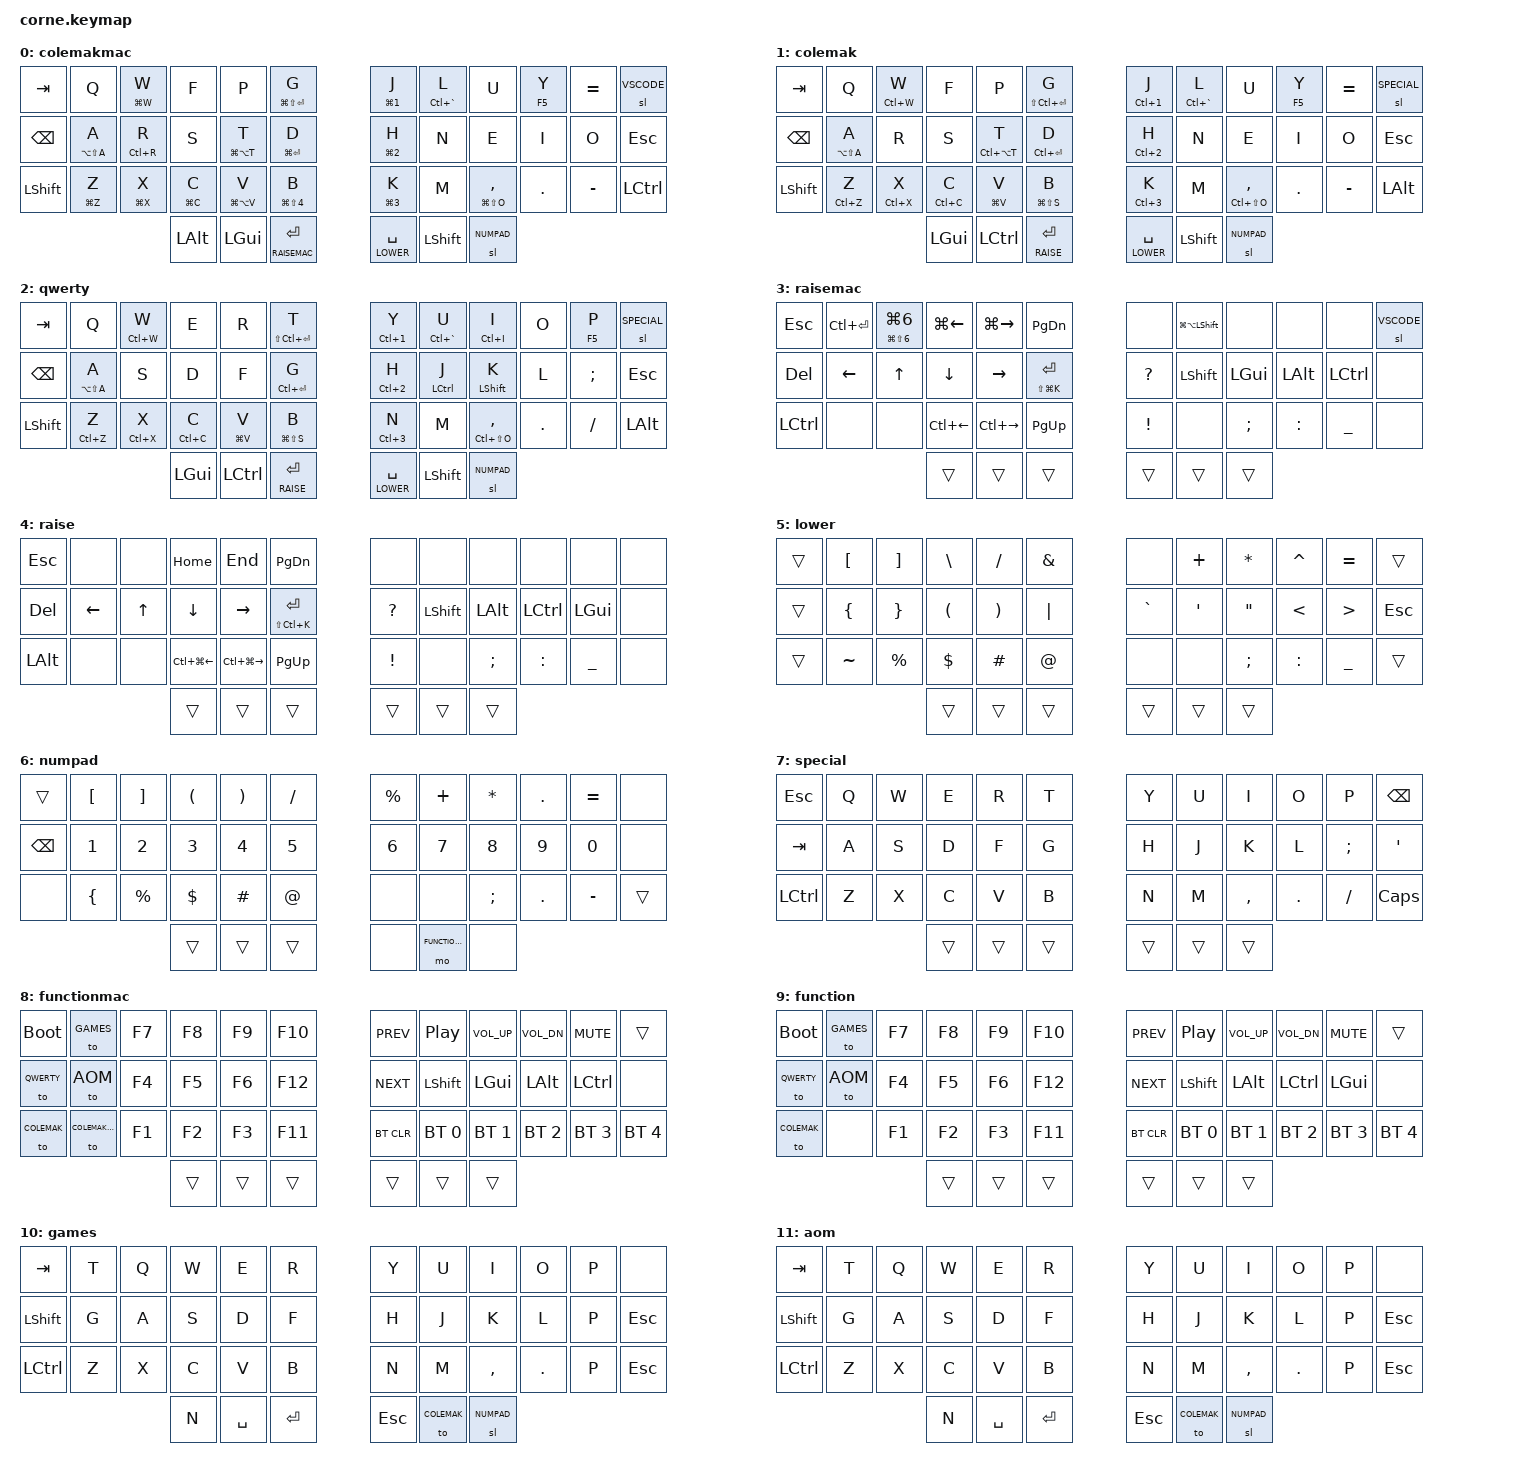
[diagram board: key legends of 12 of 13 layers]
/*
 * Copyright (c) 2020 The ZMK Contributors
 *
 * SPDX-License-Identifier: MIT
 */

#include <behaviors.dtsi>
#include <dt-bindings/zmk/outputs.h>
#include <dt-bindings/zmk/rgb.h>
#include <dt-bindings/zmk/keys.h>
#include <dt-bindings/zmk/bt.h>

//Layer definitions
#define COLEMAKMAC 0
#define COLEMAK 1
#define QWERTY 2
#define RAISEMAC 3
#define RAISE 4
#define LOWER 5
#define NUMPAD 6
#define SPECIAL 7
#define FUNCTIONMAC 8
#define FUNCTION 9
#define GAMES 10
#define AOM 11
#define VSCODE 12
#define MOOM 13
/*#define MINERAISE 8
#define ADJUST 9
*/

&caps_word {
    continue-list = <UNDERSCORE MINUS>;
};

/ {

    combos {
        compatible = "zmk,combos";
        combo_F12 {
            timeout-ms = <50>;
            key-positions = <17 16>;
            bindings = <&kp F12>;
            layers = <QWERTY COLEMAK COLEMAKMAC>;
        };
        combo_F2 {
            timeout-ms = <50>;
            key-positions = <26 27>;
            bindings = <&kp F2>;
            layers = <QWERTY COLEMAK COLEMAKMAC>;
        };
        combo_F3 {
            timeout-ms = <50>;
            key-positions = <3 4>;
            bindings = <&kp F3>;
            layers = <QWERTY COLEMAK COLEMAKMAC>;
        };
        combo_SQT {
            timeout-ms = <50>;
            key-positions = <8 9>;
            bindings = <&kp SQT>;
            layers = <QWERTY COLEMAK COLEMAKMAC>;
        };
        combo_Format {
            timeout-ms = <50>;
            key-positions = <5 4>;
            bindings = <&kp LA(LS(F))>;
            layers = <QWERTY COLEMAK COLEMAKMAC>;
        };
        combo_AltTab {
            timeout-ms = <50>;
            key-positions = <2 3>;
            bindings = <&kp LA(TAB)>;
            layers = <QWERTY COLEMAK>;
        };
        combo_AltRigth {
            timeout-ms = <50>;
            key-positions = <15 16>;
            bindings = <&kp LA(RIGHT)>;
            layers = <QWERTY COLEMAK>;
        };
        combo_AltLeft {
            timeout-ms = <50>;
            key-positions = <14 15>;
            bindings = <&kp LA(LEFT)>;
            layers = <QWERTY COLEMAK>;
        };
        combo_AltTab_MAC {
            timeout-ms = <50>;
            key-positions = <2 3>;
            bindings = <&kp LG(TAB)>;
            layers = <COLEMAKMAC>;
        };
        combo_AltRigth_MAC {
            timeout-ms = <50>;
            key-positions = <15 16>;
            bindings = <&kp LC(MINUS)>;
            layers = <COLEMAKMAC>;
        };
        combo_AltLeft_MAC {
            timeout-ms = <50>;
            key-positions = <14 15>;
            bindings = <&kp LC(LS(MINUS))>;
            layers = <COLEMAKMAC>;
        };
        combo_MissionControl {
            timeout-ms = <50>;
            key-positions = <14 15>;
            bindings = <&kp LC(UP)>;
            layers = <RAISEMAC>;
        };
        combo_Caps {
            timeout-ms = <50>;
            key-positions = <1 2>;
            bindings = <&caps_word>;
            layers = <QWERTY COLEMAK COLEMAKMAC>;
        };
    };
    behaviors {
        mt_s: ctrl_shift {
            compatible = "zmk,behavior-hold-tap";
            label = "HOMEROW_MODS_CTRL_SHIFT";
            #binding-cells = <2>;
            tapping-term-ms = <180>;
            quick_tap_ms = <0>;
            flavor = "balanced";
            bindings = <&kp>, <&kp>;
        };
        mt_m: medium {
            compatible = "zmk,behavior-hold-tap";
            label = "Fast hold";
            #binding-cells = <2>;
            tapping-term-ms = <240>;
            quick_tap_ms = <0>;
            flavor = "tap-preferred";
            bindings = <&kp>, <&kp>;
        };
        mt_l: alt_gui {
            compatible = "zmk,behavior-hold-tap";
            label = "HOMEROW_MODS_ALT_GUI";
            #binding-cells = <2>;
            tapping-term-ms = <300>;
            quick_tap_ms = <0>;
            flavor = "tap-preferred";
            bindings = <&kp>, <&kp>;
        };

    };

    keymap {
            compatible = "zmk,keymap";

            colemakmac {
// GASC home row mods. Layer key mods. Mod tap for zxcv. Mod tap for backspace/shift
// -----------------------------------------------------------------------------------------
// | 0   |  Q  |  W  |  F  |  P  |  G  |    6 |  J  |  L  |  U  |  Y  |  ;  |      |
// | 12   |  A  |  R  |  S  |  T  |  D  |  18 |  H  |  N  |  E  |  I  |  O  |  '   |
// | 24   |  Z  |  X  |  C  |  V  |  B  |  30 |  K  |  M  |  ,  |  .  |  /  | CAPS |
//                       | TAB | LWR | SPC |   | ENT | RSE | BSPC|
//                             | ESC |               | DEL |
//vscode LG(LS(0)) Go to Symbol
// mac LG(LS(N4)) screenshot (add ctrl to copy only)
        bindings = <
    &kp TAB     &kp Q              &mt_l LG(W) W    &kp F           &kp P              &mt_m LG(LS(ENTER))  G  /**/    &mt_m LG(N1) J     &mt_m LC(GRAVE) L   &kp U                     &mt_m F5 Y     &kp EQUAL        &sl VSCODE
    &kp BSPC    &mt_l LA(LS(A)) A  &mt_l LC(R) R    &kp S           &mt_l LG(LA(T)) T  &mt_m LG(ENTER)      D  /**/    &mt_m LG(N2) H     &kp N               &kp E                     &kp I          &kp O            &kp ESC
    &kp LSHFT   &mt_l LG(Z) Z      &mt_l LG(X) X    &mt_l LG(C) C   &mt_m LG(LA(V)) V  &mt_m LG(LS(N4))     B  /**/    &mt_m LG(N3) K     &kp M               &mt_m LG(LS(O)) COMMA      &kp DOT        &kp MINUS       &kp LCTRL
                                                &kp  LALT  &kp LGUI   &lt RAISEMAC ENTER                       /**/    &lt LOWER SPACE   &kp LSHFT   &sl NUMPAD
                        >;
            };      

            colemak {
// GASC home row mods. Layer key mods. Mod tap for zxcv. Mod tap for backspace/shift
// -----------------------------------------------------------------------------------------
// | 0   |  Q  |  W  |  F  |  P  |  G  |    6 |  J  |  L  |  U  |  Y  |  ;  |      |
// | 12   |  A  |  R  |  S  |  T  |  D  |  18 |  H  |  N  |  E  |  I  |  O  |  '   |
// | 24   |  Z  |  X  |  C  |  V  |  B  |  30 |  K  |  M  |  ,  |  .  |  /  | CAPS |
//                       | TAB | LWR | SPC |   | ENT | RSE | BSPC|
//                             | ESC |               | DEL |

        bindings = <
    &kp TAB     &kp Q              &mt_l LC(W) W    &kp F           &kp P              &mt_m LS(LC(ENTER))  G  /**/    &mt_m LC(N1) J     &mt_m LC(GRAVE) L   &kp U                     &mt_m F5 Y     &kp EQUAL        &sl SPECIAL
    &kp BSPC    &mt_l LA(LS(A)) A  &kp R            &kp S           &mt_l LC(LA(T)) T  &mt_m LC(ENTER)      D  /**/    &mt_m LC(N2) H     &kp N               &kp E                     &kp I          &kp O            &kp ESC
    &kp LSHFT   &mt_l LC(Z) Z      &mt_l LC(X) X    &mt_l LC(C) C   &mt_m LG(V) V      &mt_m LG(LS(S))      B  /**/    &mt_m LC(N3) K     &kp M               &mt_m LC(LS(O)) COMMA      &kp DOT        &kp MINUS       &kp LALT
                                                &kp LGUI   &kp LCTRL   &lt RAISE ENTER                         /**/    &lt LOWER SPACE   &kp LSHFT   &sl NUMPAD
                        >;
            };


            qwerty {
// GASC home row mods. Layer key mods. Mod tap for zxcv. Mod tap for backspace/shift
// -----------------------------------------------------------------------------------------
// |    |  Q  |  W  |  E  |  R  |  T  |   |  Y  |  U  |  I  |  O  |  P  |      |
// |    |  A  |  S  |  D  |  F  |  G  |   |  H  |  J  |  K  |  L  |  ;  |  '   |
// |    |  Z  |  X  |  C  |  V  |  B  |   |  N  |  M  |  ,  |  .  |  /  | CAPS |
//                       | TAB | LWR | SPC |   | ENT | RSE | BSPC|
//                             | ESC |               | DEL |
        bindings = <
    &kp TAB     &kp Q               &mt_l LC(W) W   &kp E           &kp R           &mt_m LS(LC(ENTER)) T   /**/    &mt_m LC(N1) Y   &mt_m LC(GRAVE) U  &mt_l LC(I) I           &kp O        &mt_m F5 P     &sl SPECIAL
    &kp BSPC    &mt_l LA(LS(A)) A   &kp  S          &kp D           &kp F           &mt_m LC(ENTER)     G   /**/    &mt_m LC(N2) H   &mt_s LCTRL J      &mt_s LSHFT K           &kp L        &kp SEMI       &kp ESC
    &kp LSHFT   &mt_l LC(Z) Z       &mt_l LC(X) X   &mt_l LC(C) C   &mt_l LG(V) V   &mt_m LG(LS(S))     B   /**/    &mt_m LC(N3) N   &kp M              &mt_m LC(LS(O)) COMMA   &kp DOT      &kp FSLH       &kp LALT
                                            &kp LGUI   &kp LCTRL   &lt RAISE ENTER                          /**/    &lt LOWER SPACE   &kp LSHFT   &sl NUMPAD
                        >;
            };

            raisemac {
// -----------------------------------------------------------------------------------------
// |      |  1  |  2  |  3  |  4  |  5  |   |  6  |  7  |  8  |  9  |  0  |  DEL |
// |      | HME | PGU | PGD | END | XXX |   | XXX | LFT | DWN |  UP | RGT |      |
// |      | F1  | F2  | F3  | F4  | F5  |   | F6  | F7  | F8  | F9  | F10 | CAPS |
//                    |     |     |     |   |     |     |     |
//vscode: LG (6) open explorer view (double tap: open file) (hold return to active editor)
        bindings = <
    &kp ESC  &kp LC(ENTER)  &mt_m LG(LS(N6)) LG(N6)   &kp LG(LEFT)   &kp LG(RIGHT)      &kp PG_DN             /**/   &none       &kp LG(LA(LSHFT))      &none      &none        &none       &sl VSCODE
    &kp DEL   &kp LEFT      &kp UP                     &kp DOWN       &kp  RIGHT         &mt_m LS(LG(K)) ENTER /**/   &kp QMARK   &kp LSHFT             &kp LGUI   &kp LALT     &kp LCTRL   &none
    &kp LCTRL  &none        &none                    &kp LC(LEFT)   &kp LC(RIGHT)      &kp PG_UP             /**/   &kp EXCL    &none                  &kp SEMI   &kp COLON    &kp UNDER   &none
                                   &trans       &trans                &trans                /**/   &trans      &trans         &trans
                        >;
            };

            raise {
// -----------------------------------------------------------------------------------------
// |      |  1  |  2  |  3  |  4  |  5  |   |  6  |  7  |  8  |  9  |  0  |  DEL |
// |      | HME | PGU | PGD | END | XXX |   | XXX | LFT | DWN |  UP | RGT |      |
// |      | F1  | F2  | F3  | F4  | F5  |   | F6  | F7  | F8  | F9  | F10 | CAPS |
//                    |     |     |     |   |     |     |     |
        bindings = <
    &kp ESC  &none      &none      &kp HOME     &kp END               &kp PG_DN             /**/   &none       &none          &none      &none        &none       &none
    &kp DEL   &kp LEFT  &kp UP   &kp DOWN       &kp  RIGHT            &mt_m LS(LC(K)) ENTER /**/    &kp QMARK   &kp LSHFT      &kp LALT   &kp LCTRL    &kp LGUI    &none
    &kp LALT  &none     &none      &kp LC(LG(LEFT)) &kp LC(LG(RIGHT)) &kp PG_UP             /**/   &kp EXCL    &none          &kp SEMI   &kp COLON    &kp UNDER   &none
                                   &trans       &trans                &trans                /**/    &trans      &trans         &trans
                        >;
            };


            lower {
// -----------------------------------------------------------------------------------------
// |      |  !  |  @  |  #  |  $  |  %  |   |  ^  |  &  |  *  |  {  |  }  | DEL  |
// |      |  -  |  _  |  =  |  +  |  `  |   |  ~  |  (  |  )  |  [  |  ]  |      |
// |      | Und | Cut | Cpy | Pst |     |   | PLY |  V+ |  V- | MTE |  \  |      |
//                    |     |     |     |   |     |     |     |
        bindings = <
    &trans  &kp LBKT  &kp RBKT      &kp BSLH    &kp FSLH  &kp AMPS /**/    &none      &kp PLUS       &kp STAR       &kp CARET         &kp EQUAL       &trans
    &trans  &kp LBRC  &kp RBRC       &kp LPAR   &kp RPAR    &kp PIPE   /**/    &kp GRAVE    &kp SQT    &kp DQT        &kp LT        &kp GT      &kp ESC    
    &trans  &kp TILDE &kp PERCENT    &kp DOLLAR   &kp HASH   &kp AT       /**/    &none       &none      &kp SEMI        &kp COLON    &kp UNDER   &trans
                                    &trans      &trans      &trans      /**/    &trans      &trans      &trans
                        >;
            };

            numpad {
// ---------------------------------------------------------------------------------------------------------------------------------
// |       |     |     |   [  |  ]  |  *   |   | VOL+ |  7    |  8    |  9   |       |      |
// |       |  -  |  _  |   =  |  +  |  `   |   | VOL- |  4    |  5    |  6   |   |   |      |
// |       |  {  |  }  |   (  |  )  |  ~   |   | PLAY |  1    |  2    |  3   |   \   |      |
//                     |      |     |      |   | MUTE |  0    |  .    |
        bindings = <
    &trans	  &kp LBKT    &kp RBKT   &kp LPAR   &kp RPAR 	&kp FSLH    /**/    &kp PERCENT &kp PLUS    &kp STAR	&kp DOT     &kp EQUAL   &none
	&kp BSPC  &kp N1	  &kp N2	 &kp N3      &kp N4	    &kp N5   /**/       &kp N6      &kp N7      &kp N8      &kp N9	    &kp N0  	&none
	&none     &kp LBRC &kp PERCENT    &kp DOLLAR   &kp HASH   &kp AT   /**/   	&none	    &none       &kp SEMI    &kp DOT     &kp MINUS   &trans
	                    		    &trans       &trans      &trans      /**/    &none       &mo FUNCTIONMAC    &none
                        >;
            };            
            special {
// -------------------------------------   -------------------------------------
// | ESC |  Q  |  W  |  E  |  R  |  T  |   |  Y  |  U  |  I  |  O  |  P  | BSPC|
// | TAB |  A  |  S  |  D  |  F  |  G  |   |  H  |  J  |  K  |  L  |  ;  |  '  |
// | CTRL|  Z  |  X  |  C  |  V  |  B  |   |  N  |  M  |  ,  |  .  |  /  | CAPS|
//                   | LALT| AOER|SH/SP|   |LSHFT| XXX | DEL |
// -------------------------------------   -------------------------------------
        bindings = <
    &kp ESC     &kp Q   &kp W   &kp E       &kp R               &kp T           /**/    &kp Y       &kp U       &kp I       &kp O   &kp P       &kp BSPC
    &kp TAB     &kp A   &kp S   &kp D       &kp F               &kp G           /**/    &kp H       &kp J       &kp K       &kp L   &kp SEMI    &kp SQT
    &kp LCTRL   &kp Z   &kp X   &kp C       &kp V               &kp B           /**/    &kp N       &kp M       &kp COMMA   &kp DOT &kp FSLH    &kp CAPS
                                &trans      &trans              &trans      /**/        &trans      &trans      &trans
                    >;
            };

        functionmac {
// -------------------------------------   -------------------------------------
// |  0  |  1  |  2  |  3  |  4  |  5  |   |     |     |     |     |     |     |
// |LS(0)|LS(1)|LS(2)|LS(3)|LS(4)|LS(5)|   |     |     |     |     |     |     |
// |SC(G)|SC(Q)|SC(W)|SC(E)|SC(R)|SC(T)|   |     |     |     |     |     |     |
//                   |     |     |     |   |     | ADJ |     |
// -------------------------------------   -------------------------------------
        bindings = <
    &bootloader     &to GAMES       &kp F7   &kp F8   &kp F9   &kp F10   /**/    &kp C_PREV     &kp C_PLAY_PAUSE   &kp C_VOL_UP    &kp C_VOL_DN      &kp C_MUTE         &trans
    &to QWERTY      &to AOM         &kp F4   &kp F5   &kp F6   &kp F12   /**/    &kp C_NEXT     &kp LSHFT           &kp LGUI        &kp LALT        &kp LCTRL       &none
    &to COLEMAK     &to COLEMAKMAC  &kp F1   &kp F2   &kp F3   &kp F11  /**/     &bt BT_CLR  &bt BT_SEL 0    &bt BT_SEL 1 &bt BT_SEL 2   &bt BT_SEL 3    &bt BT_SEL 4 
                         &trans    &trans       &trans          /**/     &trans       &trans     &trans
                    >;
            };

            function {
// -------------------------------------   -------------------------------------
// |  0  |  1  |  2  |  3  |  4  |  5  |   |     |     |     |     |     |     |
// |LS(0)|LS(1)|LS(2)|LS(3)|LS(4)|LS(5)|   |     |     |     |     |     |     |
// |SC(G)|SC(Q)|SC(W)|SC(E)|SC(R)|SC(T)|   |     |     |     |     |     |     |
//                   |     |     |     |   |     | ADJ |     |
// -------------------------------------   -------------------------------------
        bindings = <
    &bootloader     &to GAMES   &kp F7   &kp F8   &kp F9   &kp F10   /**/    &kp C_PREV     &kp C_PLAY_PAUSE   &kp C_VOL_UP    &kp C_VOL_DN      &kp C_MUTE         &trans
    &to QWERTY      &to AOM     &kp F4   &kp F5   &kp F6   &kp F12   /**/    &kp C_NEXT     &kp LSHFT       &kp LALT     &kp LCTRL      &kp LGUI        &none
    &to COLEMAK     &none       &kp F1   &kp F2   &kp F3   &kp F11  /**/     &bt BT_CLR  &bt BT_SEL 0    &bt BT_SEL 1 &bt BT_SEL 2   &bt BT_SEL 3    &bt BT_SEL 4 
                         &trans    &trans       &trans          /**/     &trans       &trans     &trans
                    >;
            };


    games {

        bindings = <
    &kp TAB     &kp T       &kp  Q      &kp W       &kp E        &kp R      /**/    &kp Y   &kp U       &kp I           &kp O       &kp P           &none
    &kp LSHFT   &kp G       &kp  A      &kp S       &kp D        &kp F      /**/    &kp H   &kp J       &kp K           &kp L       &kp P        &kp ESC
    &kp LCTRL   &kp Z       &kp  X      &kp C       &kp V        &kp B      /**/    &kp N   &kp M       &kp COMMA       &kp DOT     &kp P        &kp ESC
                                        &kp N   &kp SPACE   &kp ENTER       /**/    &kp ESC   &to COLEMAK   &sl NUMPAD
                        >;
    };


    aom { // not developed

    bindings = <
    &kp TAB     &kp T       &kp  Q      &kp W       &kp E        &kp R      /**/    &kp Y   &kp U       &kp I           &kp O       &kp P           &none
    &kp LSHFT   &kp G       &kp  A      &kp S       &kp D        &kp F      /**/    &kp H   &kp J       &kp K           &kp L       &kp P        &kp ESC
    &kp LCTRL   &kp Z       &kp  X      &kp C       &kp V        &kp B      /**/    &kp N   &kp M       &kp COMMA       &kp DOT     &kp P        &kp ESC
                                        &kp N   &kp SPACE   &kp ENTER       /**/    &kp ESC   &to COLEMAK   &sl NUMPAD
                        >;
        };

    vscode { // not developed
// focus next group into next group LG 8 ( previous LG 7)
// move editor into next group LG LS 7
// goToNextSymbol LS LA LG Down/Up
// go next edit location LS LA LG RIGHT/LEFT
// goto prev next tab in group LA(LG(LEFT)) 
    bindings = <
    &kp TAB             &kp LA(LG(LEFT))       &kp LS(LA(F8))        &kp LA(F8)              &kp LA(LG(RIGHT))      &kp T            /**/    &kp Y   &kp U       &kp I           &kp O       &kp P           &none
    &kp LG(LS(N7))      &kp LG(N7)             &kp LS(LA(LG(UP)))    &kp LS(LA(LG(DOWN)))    &kp LG(N8)        &kp LG(LS(N8))   /**/    &kp H   &kp J       &kp K           &kp L       &kp P        &kp ESC
    &kp LCTRL           &kp X                  &kp LS(LA(LG(LEFT)))  &kp LS(LA(LG(RIGHT)))   &kp B             &kp Z            /**/    &kp N   &kp M       &kp COMMA       &kp DOT     &kp P        &kp ESC
                                        &kp N   &kp LSHFT    &lt RAISEMAC ENTER                                                 /**/    &kp ESC    &kp LSHFT    &sl NUMPAD
                        >;
        };
    };
};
